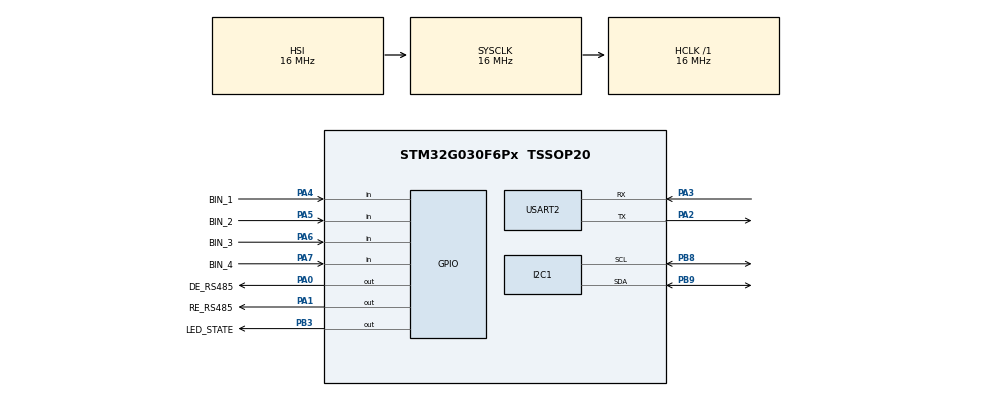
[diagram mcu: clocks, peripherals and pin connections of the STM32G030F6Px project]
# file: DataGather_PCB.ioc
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I2C1.Timing=0x00503D58
Mcu.Family=STM32G0
Mcu.Name=STM32G030F6Px
Mcu.Package=TSSOP20
NVIC.TIM3_IRQn=true\:0\:0\:false\:false\:true\:true\:true\:true
NVIC.USART2_IRQn=true\:0\:0\:false\:false\:true\:true\:true\:true
PA0.GPIO_Label=DE_RS485
PA0.Signal=GPIO_Output
PA1.GPIO_Label=RE_RS485
PA1.Signal=GPIO_Output
PA14-BOOT0__PA15.StandardMode=true
PA2.Mode=Asynchronous
PA2.Signal=USART2_TX
PA3.Mode=Asynchronous
PA3.Signal=USART2_RX
PA4.GPIO_Label=BIN_1
PA4.Signal=GPIO_Input
PA5.GPIO_Label=BIN_2
PA5.Signal=GPIO_Input
PA6.GPIO_Label=BIN_3
PA6.Signal=GPIO_Input
PA7.GPIO_Label=BIN_4
PA7.Signal=GPIO_Input
PB0__PB1__PB2__PA8.StandardMode=true
PB3.GPIO_Label=LED_STATE
PB3.Signal=GPIO_Output
PB3__PB4__PB5__PB6.StandardMode=true
PB7__PB8.StandardMode=true
PB8.Mode=I2C
PB8.Signal=I2C1_SCL
PB9.Mode=I2C
PB9.Signal=I2C1_SDA
PC14-OSC32_IN\ (PC14)__PB9.StandardMode=true
ProjectManager.HeapSize=0x200
ProjectManager.StackSize=0x400
ProjectManager.TargetToolchain=CMake
RCC.AHBFreq_Value=16000000
RCC.CortexFreq_Value=16000000
RCC.EXTERNAL_CLOCK_VALUE=12288000
RCC.HCLKFreq_Value=16000000
RCC.HSE_VALUE=8000000
RCC.HSI_VALUE=16000000
RCC.LSE_VALUE=32768
RCC.SYSCLKFreq_VALUE=16000000
RCC.VCOOutputFreq_Value=128000000
TIM3.AutoReloadPreload=TIM_AUTORELOAD_PRELOAD_ENABLE
TIM3.Period=303
TIM3.Prescaler=15
TIM3.TIM_MasterOutputTrigger=TIM_TRGO_UPDATE
USART2.VirtualMode-Asynchronous=VM_ASYNC
VP_TIM3_VS_ClockSourceINT.Mode=Internal
board=custom

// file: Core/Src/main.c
/* USER CODE BEGIN Header */
/**
  ******************************************************************************
  * @file           : main.c
  * @brief          : Main program body
  ******************************************************************************
  * @attention
  *
  * Copyright (c) 2025 STMicroelectronics.
  * All rights reserved.
  *
  * This software is licensed under terms that can be found in the LICENSE file
  * in the root directory of this software component.
  * If no LICENSE file comes with this software, it is provided AS-IS.
  *
  ******************************************************************************
  */
/* USER CODE END Header */
#include "main.h"

/* USER CODE BEGIN Includes */
#include "datacollect.h"
#include "init.h"
#include "rs485dock.h"
#include "stm32g0xx_hal.h"
/* USER CODE END Includes */

I2C_HandleTypeDef hi2c1;

TIM_HandleTypeDef htim3;

UART_HandleTypeDef huart2;

void SystemClock_Config(void);
static void MX_GPIO_Init(void);
static void MX_I2C1_Init(void);
static void MX_USART2_UART_Init(void);
static void MX_TIM3_Init(void);

int main(void)
{

  /* MCU Configuration--------------------------------------------------------*/

  /* Reset of all peripherals, Initializes the Flash interface and the Systick. */

  HAL_Init();

  /* Configure the system clock */
  SystemClock_Config();

  /* Initialize all configured peripherals */
  MX_GPIO_Init();
  MX_I2C1_Init();
  MX_USART2_UART_Init();
  MX_TIM3_Init();
  /* USER CODE BEGIN 2 */
  HAL_GPIO_WritePin(LED_STATE_GPIO_Port, LED_STATE_Pin, GPIO_PIN_SET);
  CLEAR_BIT(huart2.Instance->CR1, USART_CR1_TE);
  InitSensors();
  RS485_Init(&huart2, &htim3);
  /* USER CODE END 2 */

  /* Infinite loop */
  /* USER CODE BEGIN WHILE */
  while (1)
  {
    CollectData();
    RS485_UpdateRegisters();
    RS485_Process();
    /* USER CODE END WHILE */

  }
}

void SystemClock_Config(void)
{
  RCC_OscInitTypeDef RCC_OscInitStruct = {0};
  RCC_ClkInitTypeDef RCC_ClkInitStruct = {0};

  /** Configure the main internal regulator output voltage
  */
  HAL_PWREx_ControlVoltageScaling(PWR_REGULATOR_VOLTAGE_SCALE1);

  /** Initializes the RCC Oscillators according to the specified parameters
  * in the RCC_OscInitTypeDef structure.
  */
  RCC_OscInitStruct.OscillatorType = RCC_OSCILLATORTYPE_HSI;
  RCC_OscInitStruct.HSIState = RCC_HSI_ON;
  RCC_OscInitStruct.HSIDiv = RCC_HSI_DIV1;
  RCC_OscInitStruct.HSICalibrationValue = RCC_HSICALIBRATION_DEFAULT;
  RCC_OscInitStruct.PLL.PLLState = RCC_PLL_NONE;
  if (HAL_RCC_OscConfig(&RCC_OscInitStruct) != HAL_OK)
  {
    Error_Handler();
  }

  /** Initializes the CPU, AHB and APB buses clocks
  */
  RCC_ClkInitStruct.ClockType = RCC_CLOCKTYPE_HCLK|RCC_CLOCKTYPE_SYSCLK
                              |RCC_CLOCKTYPE_PCLK1;
  RCC_ClkInitStruct.SYSCLKSource = RCC_SYSCLKSOURCE_HSI;
  RCC_ClkInitStruct.AHBCLKDivider = RCC_SYSCLK_DIV1;
  RCC_ClkInitStruct.APB1CLKDivider = RCC_HCLK_DIV1;

  if (HAL_RCC_ClockConfig(&RCC_ClkInitStruct, FLASH_LATENCY_0) != HAL_OK)
  {
    Error_Handler();
  }
}

static void MX_I2C1_Init(void)
{

  hi2c1.Instance = I2C1;
  hi2c1.Init.Timing = 0x00503D58;
  hi2c1.Init.OwnAddress1 = 0;
  hi2c1.Init.AddressingMode = I2C_ADDRESSINGMODE_7BIT;
  hi2c1.Init.DualAddressMode = I2C_DUALADDRESS_DISABLE;
  hi2c1.Init.OwnAddress2 = 0;
  hi2c1.Init.OwnAddress2Masks = I2C_OA2_NOMASK;
  hi2c1.Init.GeneralCallMode = I2C_GENERALCALL_DISABLE;
  hi2c1.Init.NoStretchMode = I2C_NOSTRETCH_DISABLE;
  if (HAL_I2C_Init(&hi2c1) != HAL_OK)
  {
    Error_Handler();
  }

  /** Configure Analogue filter
  */
  if (HAL_I2CEx_ConfigAnalogFilter(&hi2c1, I2C_ANALOGFILTER_ENABLE) != HAL_OK)
  {
    Error_Handler();
  }

  /** Configure Digital filter
  */
  if (HAL_I2CEx_ConfigDigitalFilter(&hi2c1, 0) != HAL_OK)
  {
    Error_Handler();
  }

}

static void MX_TIM3_Init(void)
{

  TIM_ClockConfigTypeDef sClockSourceConfig = {0};
  TIM_MasterConfigTypeDef sMasterConfig = {0};

  htim3.Instance = TIM3;
  htim3.Init.Prescaler = 15;
  htim3.Init.CounterMode = TIM_COUNTERMODE_UP;
  htim3.Init.Period = 303;
  htim3.Init.ClockDivision = TIM_CLOCKDIVISION_DIV1;
  htim3.Init.AutoReloadPreload = TIM_AUTORELOAD_PRELOAD_ENABLE;
  if (HAL_TIM_Base_Init(&htim3) != HAL_OK)
  {
    Error_Handler();
  }
  sClockSourceConfig.ClockSource = TIM_CLOCKSOURCE_INTERNAL;
  if (HAL_TIM_ConfigClockSource(&htim3, &sClockSourceConfig) != HAL_OK)
  {
    Error_Handler();
  }
  sMasterConfig.MasterOutputTrigger = TIM_TRGO_UPDATE;
  sMasterConfig.MasterSlaveMode = TIM_MASTERSLAVEMODE_DISABLE;
  if (HAL_TIMEx_MasterConfigSynchronization(&htim3, &sMasterConfig) != HAL_OK)
  {
    Error_Handler();
  }

}

static void MX_USART2_UART_Init(void)
{

  huart2.Instance = USART2;
  huart2.Init.BaudRate = 115200;
  huart2.Init.WordLength = UART_WORDLENGTH_8B;
  huart2.Init.StopBits = UART_STOPBITS_1;
  huart2.Init.Parity = UART_PARITY_NONE;
  huart2.Init.Mode = UART_MODE_TX_RX;
  huart2.Init.HwFlowCtl = UART_HWCONTROL_NONE;
  huart2.Init.OverSampling = UART_OVERSAMPLING_16;
  huart2.Init.OneBitSampling = UART_ONE_BIT_SAMPLE_DISABLE;
  huart2.Init.ClockPrescaler = UART_PRESCALER_DIV1;
  huart2.AdvancedInit.AdvFeatureInit = UART_ADVFEATURE_NO_INIT;
  if (HAL_UART_Init(&huart2) != HAL_OK)
  {
    Error_Handler();
  }

}

static void MX_GPIO_Init(void)
{
  GPIO_InitTypeDef GPIO_InitStruct = {0};

  /* GPIO Ports Clock Enable */
  __HAL_RCC_GPIOB_CLK_ENABLE();
  __HAL_RCC_GPIOA_CLK_ENABLE();

  /*Configure GPIO pin Output Level */
  HAL_GPIO_WritePin(GPIOA, DE_RS485_Pin|RE_RS485_Pin, GPIO_PIN_RESET);

  /*Configure GPIO pin Output Level */
  HAL_GPIO_WritePin(LED_STATE_GPIO_Port, LED_STATE_Pin, GPIO_PIN_RESET);

  /*Configure GPIO pins : DE_RS485_Pin RE_RS485_Pin */
  GPIO_InitStruct.Pin = DE_RS485_Pin|RE_RS485_Pin;
  GPIO_InitStruct.Mode = GPIO_MODE_OUTPUT_PP;
  GPIO_InitStruct.Pull = GPIO_NOPULL;
  GPIO_InitStruct.Speed = GPIO_SPEED_FREQ_LOW;
  HAL_GPIO_Init(GPIOA, &GPIO_InitStruct);

  /*Configure GPIO pins : BIN_1_Pin BIN_2_Pin BIN_3_Pin BIN_4_Pin */
  GPIO_InitStruct.Pin = BIN_1_Pin|BIN_2_Pin|BIN_3_Pin|BIN_4_Pin;
  GPIO_InitStruct.Mode = GPIO_MODE_INPUT;
  GPIO_InitStruct.Pull = GPIO_NOPULL;
  HAL_GPIO_Init(GPIOA, &GPIO_InitStruct);

  /*Configure GPIO pin : LED_STATE_Pin */
  GPIO_InitStruct.Pin = LED_STATE_Pin;
  GPIO_InitStruct.Mode = GPIO_MODE_OUTPUT_PP;
  GPIO_InitStruct.Pull = GPIO_NOPULL;
  GPIO_InitStruct.Speed = GPIO_SPEED_FREQ_LOW;
  HAL_GPIO_Init(LED_STATE_GPIO_Port, &GPIO_InitStruct);

}

void Error_Handler(void)
{
  __disable_irq();
  while (1)
  {
  }
}
